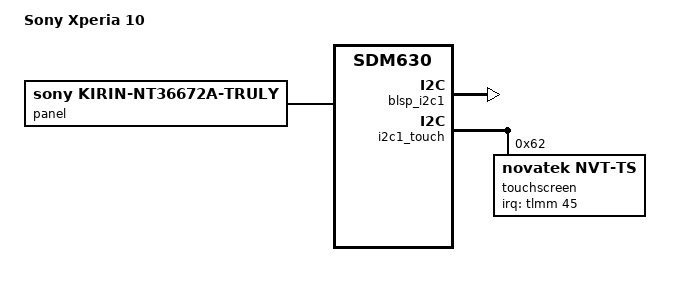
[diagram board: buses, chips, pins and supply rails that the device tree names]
// SPDX-License-Identifier: BSD-3-Clause
/*
 * Copyright (c) 2020, Martin Botka
 */

/dts-v1/;

/* To make for less clutter, kirin will include
 * nile code and mermaid will not due to the SoC
 * difference.
 */
#include "sdm630-sony-xperia-nile.dtsi"

/ {
	model = "Sony Xperia 10";
	compatible = "sony,kirin-row", "qcom,sdm630";
};

&blsp_i2c1 {
	status = "okay";

	/* Novatek touchscreen - see the note in -nile. dtsi */
};

&framebuffer0 {
	reg = <0 0x9d400000 0 (2520 * 1080 * 4)>;
	height = <2520>;
};

&gpio_keys {
	/delete-node/ camera_focus;
	/delete-node/ camera_snapshot;
};

&i2c1_touch {
	/delete-node/ synaptics-rmi4-i2c@70;

	touchscreen: novatek@62 {
		compatible = "novatek,NVT-ts";
		reg = <0x62>;
		status = "okay";

		novatek,irq-gpio = <&tlmm 45 0x2002>;
	};
};

&panel {
	compatible = "sony,kirin-nt36672a-truly";
};
